# C6424_cslr_ccdc_001 register map
Vendor: Texas Instruments
Peripheral module from a debugger description file.
Registers are 32-bit, access not given, reset 0x0 unless marked. A register's access mark holds for its fields unless they carry their own. Offsets are as the file gives them; lines under a group give offsets from that group; [hi:lo] are bit positions; {n}, {i} and the like mark numbered series; 'fields as' and 'values as' point back to an identical list; <NAME> marks a mode.

## CCDC — CCD Controller (spec version: 1.00.w.29)
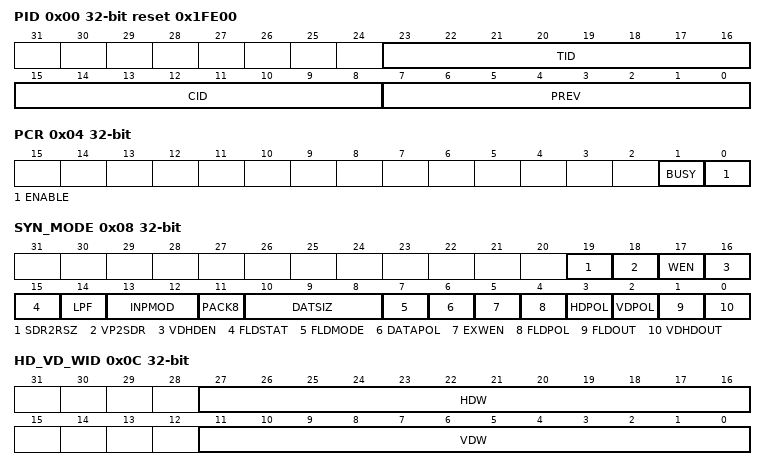
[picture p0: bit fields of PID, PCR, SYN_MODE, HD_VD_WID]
0x00 PID reset 0x1FE00 — Peripheral Revision and Class Information
  [23:16] TID ro — Peripheral Identification CCD/CMOS controller
  [15:8] CID ro — Class Identification VPFE module
  [7:0] PREV ro — Peripheral Revision Number Initial Revision
0x04 PCR — Peripheral Control Register
  [1] BUSY ro — CCDC Busy bit
    0=NOTBUSY; 1=BUSY
  [0] ENABLE rw — CCDC Enable
    0=DISABLE; 1=ENABLE
0x08 SYN_MODE — SYNC and Mode set register
  [19] SDR2RSZ rw — SDRAM port output into resizer input Controls whether or not SDRAM output data is forwarded to the resizer input port
    0=DISABLE; 1=ENABLE
  [18] VP2SDR rw — Video port output into the SDRAM port Controls whether or not video port data is forwarded to the output formatter, which in turn writes to SDRAM. Note that if field is set, then SDRAM line (VERT_START.SLVx) and pixel start (HORZ_INFO.SPH) are with respect to the video port output (and not the original input) *This bit is latched by VD
    0=DISABLE; 1=ENABLE
  [17] WEN rw — Data Write Enable Controls whether or not CCD raw data is written to SDRAM. *This bit is latched by VD
    0=DISABLE; 1=ENABLE
  [16] VDHDEN rw — VD/HD Enable If VD/HD are defined as output, activates internal timing generator. If VD/HD are defined as inputs, activates internal timing generator to synchronize with VD/HD
    0=DISABLE; 1=ENABLE
  [15] FLDSTAT ro — Field Status Indicates the status of the current field when in interlaced mode
    0=ODDFIELD; 1=EVENFIELD
  [14] LPF rw — 3-tap Low-Pass (anti-aliasing) Filter *This bit is latched by VD
    0=OFF; 1=ON
  [13:12] INPMOD rw — Setting of data input mode
    0=CCDRAW (CCD RAW data); 1=YCBCR16 (YCbCr 16-bit); 2=YCBCR8 (YCbCr 8-bit)
  [11] PACK8 rw — Pack to 8-bits/pixel (into SDRAM)
    0=_16BITS_PIXEL (normal (16 bits/pixel)); 1=_8BITS_PIXEL (pack to 8-bits/pixel)
  [10:8] DATSIZ rw — CCD Data Width valid only when INPMOD is set to '0'
    0=_16_BITS; 1=_15_BITS; 2=_14_BITS; 3=_13_BITS; 4=_12_BITS; 5=_11_BITS; 6=_10_BITS; 7=_8_BITS
  [7] FLDMODE rw — Sensor Field Mode
    0=NON_INTERLACED (non-interlaced (progressive)); 1=INTERLACED
  [6] DATAPOL rw — CCD Data Polarity
    0=NORMAL (normal (no change)); 1=ONES_COMPLEMENT
  [5] EXWEN rw — External WEN Selection When set to 1 and when VDHDEN is set to 1, the WEN signal is used as the external memory write enable (to SDRAM/DDRAM). The data is stored to memory only when the external sync (HD and VD) signals are active.
    0=NO_EXTERNAL_WEN (do not use external WEN (Write Enable)); 1=EXTERNAL_WEN (use external WEN (Write Enable))
  [4] FLDPOL rw — Field Indicator Polarity
    0=POSITIVE; 1=NEGATIVE
  [3] HDPOL rw — HD Sync Polarity
    0=POSITIVE; 1=NEGATIVE
  [2] VDPOL rw — VD Sync Polarity
    0=POSITIVE; 1=NEGATIVE
  [1] FLDOUT rw — Field ID Direction
    0=INPUT; 1=OUTPUT
  [0] VDHDOUT rw — VD/HD Sync Direction
    0=INPUT; 1=OUTPUT
0x0C HD_VD_WID — HD and VD signal width
  [27:16] HDW rw — Width of HD sync pulse if output HDW+1 pixel clocks HDWIDTH is not used when HD is input, i.e when VDHDOUT in SYN_MODE register is cleared to '0' *This bit field is latched by VD
  [11:0] VDW rw — Width of VD sync pulse if output VDW+1 lines VDWIDTH is not used when VD is input, i.e when VDHDOUT in SYN_MODE register is cleared to '0' *This bit field is latched by VD
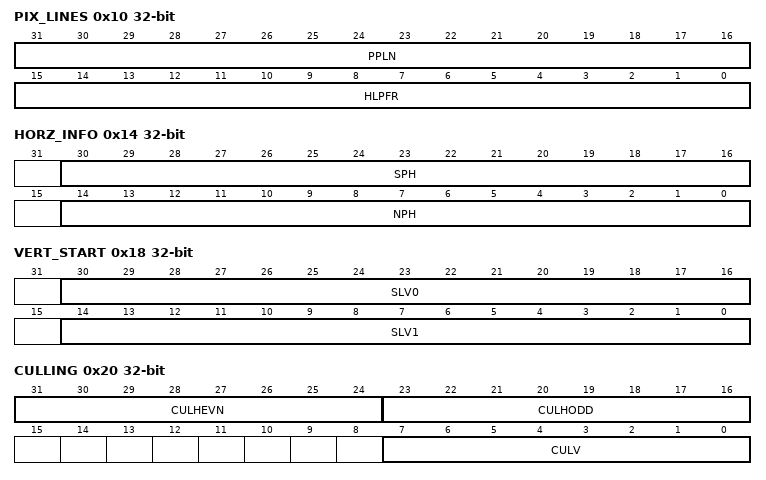
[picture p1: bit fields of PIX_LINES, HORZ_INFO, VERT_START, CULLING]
0x10 PIX_LINES rw — Number of pixels in a horizontal line and number of lines in a frame
  [31:16] PPLN — Pixels per line - number of pixel clock periods in one line HD period = PPLN+1 pixel clocks PPLN is not used when HD and VD are inputs, i.e when VDHDOUT in SYN_MODE register is cleared to '0' *This bit field is latched by VD
  [15:0] HLPFR — Half lines per field or frame - sets number of half lines per frame or field VD period = (HLPFR+1)/2 lines LPFR is not used when HD and VD are inputs, i.e when VDHDOUT in SYN_MODE register is cleared to '0' *This bit field is latched by VD This tells the internal timing generator to generate the sufficient number of HD pulses in between two VD pulses. If the sensor is an interlaced sensor, say for example, with a total of 525 (or 526) lines, then this field should be set to 525 (or 526). This means that 525 (or 526) half lines are written for each field. If the sensor is progressive, then this register should be set to be twice the number of lines to be written. For example, if sensor outputs 1024 lines, this field should be set to 2048. Therefore, for interlaced sensors, this field should be set to the total number of lines. For progressive sensors, this field should be set to twice the total number of lines.
0x14 HORZ_INFO — Horizontal pixel information
  [30:16] SPH rw — Start pixel, horizontal Sets pixel clock position at which data output to SDRAM begins, measured from the start of HD *This bit field is latched by VD
  [14:0] NPH rw — Number of pixels, horizontal Sets number of horizontal pixels that will be output to SDRAM = (NPH + 1) *This bit field is latched by VD
0x18 VERT_START — Vertical line - settings for the starting pixel
  [30:16] SLV0 rw — Start Line, Vertical (Field 0) Sets line at which data output to SDRAM will begin, measured from the start of VD *This bit field is latched by VD
  [14:0] SLV1 rw — Start Line, Vertical (Field 1) Sets line at which data output to SDRAM will begin, measured from the start of VD *This bit field is latched by VD
0x1C VERT_LINES — Number of vertical lines
  [14:0] NLV rw — Number of lines, vertical Sets number of vertical lines that will be output to SDRAM for each field. The number of lines output to SDRAM for each field = (NLV + 1). *This bit field is latched by VD
0x20 CULLING (reset mask 0xFF00) — Culling information in horizontal and vertical directions
  [31:24] CULHEVN rw — Horizontal Culling Pattern for Even Line, 8-bit mask: 0: cull, 1:retain LSB is first pixel, MSB is 8th pixel, then pattern repeats *This bit field is latched by VD
  [23:16] CULHODD rw — Horizontal Culling Pattern for Odd Line, 8-bit mask: 0: cull, 1:retain LSB is first pixel, MSB is 8th pixel, then pattern repeats *This bit field is latched by VD
  [7:0] CULV rw — Vertical Culling Pattern, 8-bit mask: 0: cull, 1:retain LSB is first line, MSB is 8th line, then pattern repeats. *This bit field is latched by VD
0x24 HSIZE_OFF — Horizontal size
  [15:0] LNOFST rw — Address offset for each line. Sets offset for each output line in SDRAM Either 16 or 32 pixels depending on setting of PACK8 *This bit field is latched by VD The 5 LSB are ignored; the offset will be on a 32-byte boundary For optimal performance in the system, the address offset should be on a 256-byte boundary.
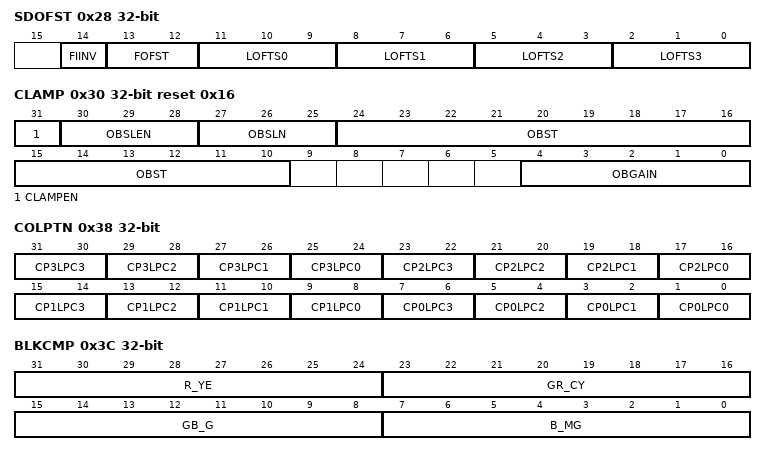
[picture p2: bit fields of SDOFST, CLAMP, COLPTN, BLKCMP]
0x28 SDOFST — SDRAM/DDRAM line offset
  [14] FIINV rw — Field identification signal inverse * This field is latched by VD
    0=NONINVERSE; 1=INVERSE
  [13:12] FOFST rw — Line offset value of field ID = 1 * This field is latched by VD
    {v}=PLUS_{v+1}LINE (+{v+1} line) (v=0..3)
  [11:9] LOFTS0 rw — Line offset values of even line and even field ID = 0 * This field is latched by VD
    0=PLUS_1LINE (+1 line); 1=PLUS_2LINES (+2 lines); 2=PLUS_3LINES (+3 lines); 3=PLUS_4LINES (+4 lines); 4=MINUS_1LINE (-1 line); 5=MINUS_2LINES (-2 lines); 6=MINUS_3LINES (-3 lines); 7=MINUS_4LINES (-4 lines)
  [8:6] LOFTS1 rw — Line offset values of odd line and even field ID = 0 * This field is latched by VD
    values as LOFTS0
  [5:3] LOFTS2 rw — Line offset values of even line and odd field ID = 1 * This field is latched by VD
    values as LOFTS0
  [2:0] LOFTS3 rw — Line offset values of odd line and odd field ID = 1 * This field is latched by VD
    values as LOFTS0
0x2C SDR_ADDR rw — SDRAM Address
  [31:0] SDR_ADDR — 32-bit SDRAM starting address for CCDC output *This bit field is latched by VD Note that the address should be aligned on a 32-byte boundary. Therefore, the 5 LSB's are ignored. Furthermore, reading this register will always show the 5 LSB's as 0. For optimal performance in the system, the address should be on a 256-byte boundary.
0x30 CLAMP reset 0x16 — Optical black clamping settings
  [31] CLAMPEN rw — Clamp Enable: Enables clamping of CCD data based on the calculated average of Optical Black Samples. *This bit is latched by VD
    0=DISABLE; 1=ENABLE
  [30:28] OBSLEN rw — Optical Black Sample Length 5-7: Reserved Number of Optical Black Sample pixels per line to include in the average calculation
    0=_1PIXELS; 1=_2PIXELS; 2=_4PIXELS; 3=_8PIXELS; 4=_16PIXELS
  [27:25] OBSLN rw — Optical Black Sample Lines 5-7: Reserved Number of Optical Black Sample lines to include in the average calculation
    0=_1LINES; 1=_2LINES; 2=_4LINES; 3=_8LINES; 4=_16LINES
  [24:10] OBST rw — Start Pixel of Optical Black Samples Start pixel position of Optical Black Samples, specified from the start of HD in pixel clocks
  [4:0] OBGAIN rw — Gain to apply to the optical black average Multiply the optical black average with the specified gain (range from 0 to ~2 - U5Q4)
0x34 DCSUB — DC clamp
  [13:0] DCSUB rw — DC level to subtract from CCD data The DC value set here is subtracted from the CCD data when OBS clamping is disabled - CLAMP:CLAMPEN
0x38 COLPTN rw — CCD color pattern
  [all] fields
    0=R; 1=GR; 2=GB; 3=B
  [2n+25:2n+24] CP3LPC{n} (n=0..3) — Color Pattern for 3rd Line, Pixel counter = {n}
  [2n+17:2n+16] CP2LPC{n} (n=0..3) — Color Pattern for 2nd Line, Pixel counter = {n}
  [2n+9:2n+8] CP1LPC{n} (n=0..3) — Color Pattern for 1st Line, Pixel counter = {n}
  [2n+1:2n] CP0LPC{n} (n=0..3) — Color Pattern for 0th Line, Pixel counter = {n}
0x3C BLKCMP rw — Black compensation
  [31:24] R_YE — Black level compensation for R pixels (-128:+127) 2's complement, MSB is sign bit
  [23:16] GR_CY — Black level compensation for Gr pixels (-128:+127) 2's complement, MSB is sign bit
  [15:8] GB_G — Black level compensation for Gb pixels (-128:+127) 2's complement, MSB is sign bit
  [7:0] B_MG — Black level compensation for B pixels (-128:+127) 2's complement, MSB is sign bit
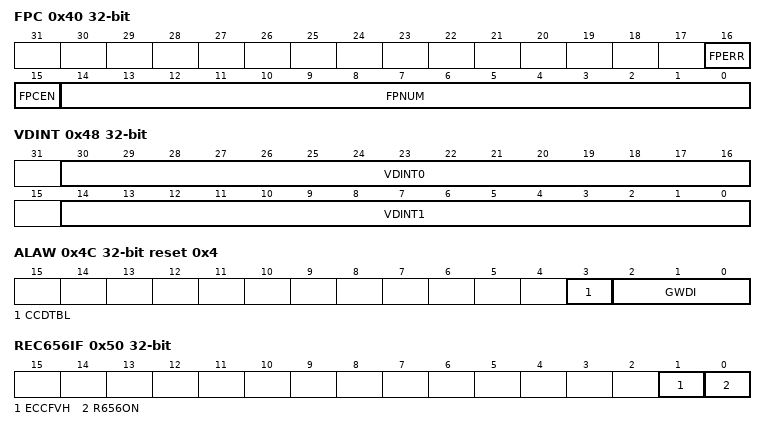
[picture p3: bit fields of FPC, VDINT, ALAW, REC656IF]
0x40 FPC — Fault pixel correction
  [16] FPERR rw — Fault pixel correction error Write 1 to clear the error This bit is set when the CCDC is unable to fetch the required fault pixel table entry in time for it to correct it. For example, the current pixel being processed has coordinates of 256/512 (256th line and 512th pixel in that line) and it needs to be corrected. If the entry in the fault pixel table that needs to be used has coordinates 256/256, then the current pixel cannot be corrected since the correct entry is not loaded in time. Note that there is no error recovery mechanism in the CCDC; if this bit is set at anytime in a frame, there will no more fault pixels corrected in that frame. Firmware is responsible for making sure that there is enough bandwidth in the system to allow for loading of the fault pixel table. Alternately, decreasing the frequency of the fault pixels to be corrected will enhance chances of this bit not being set.
    0=NOERROR; 1=ERROR
  [15] FPCEN rw — Fault pixel correction enable Upon setting this bit and as long as it remains enabled the fault pixel logic will continue to request data and just start over once the last data has been received. As soon as the register is set the data will be fetched This bit should only be written after the FPC_ADDR register below has been set. Also, the other fields in this register have to be set prior to enabling this bit. The required process is: Write(FPC_ADDR) Write(FPC) with this bit (FPC.FPCEN) turned off Write(FPC) with this bit (FPC.FPCEN) turned on while other fields are same as previous write
    0=DISABLED; 1=ENABLED
  [14:0] FPNUM rw — Number of fault pixels to be corrected in the frame *This field is latched by VD
0x44 FPC_ADDR rw — Fault pixel correction SDRAM address
  [31:0] FPC_ADDR — Starting SDRAM/DDRAM address of the fault pixel correction entries Note that the address should be aligned to a 64-byte boundary, therefore, the 6 LSB's are ignored Each of the 32-bit fault memory entry contains a 13-bit vertical position, a 14-bit horizontal position, and a 5-bit operation field The following operations are decoded by the 5-bit operation field (4:0) Note that "x" denotes the horizontal coordinate 0: replace pixel at x with the average of x-1 and x+1 1: replace pixel at x with the x-1 2: replace pixel at x with the x+1 3: replace pixel at x with the average of x-2 and x+2 4: replace pixel at x with the x-2 5: replace pixel at x with the x+2 6: replace pixel at x with the average of x-3 and x+3 7: replace pixel at x with the x-3 8: replace pixel at x with the x+3 9: replace pixel at x with the average of x-4 and x+4 10: replace pixel at x with the x-4 11: replace pixel at x with the x+4 12: replace pixel at x with the average of x-5 and x+5 13: replace pixel at x with the x-5 14: replace pixel at x with the x+5 15: replace pixel at x with the average of x-6 and x+6 16: replace pixel at x with the x-6 17: replace pixel at x with the x+6 18-31: RESERVED
0x48 VDINT — VD Interrupt Timing
  [30:16] VDINT0 rw — VD0 Interrupt Timing Specify VDINT0 in units of horiziontal lines from the start of VD pulse . Resulting value is VDINT0 + 1. Note that if the rising edge (or falling edge if programmed) of the HD lines up with the rising edge (or falling edge if programmed) of VD, the 1st HD is not counted.
  [14:0] VDINT1 rw — VD1 Interrupt Timing Specify VDINT1 in units of horizontal lines from the start of VD pulse. Resulting value is VDINT1 + 1. Note that if the rising edge (or falling edge if programmed) of the HD lines up with the rising edge (or falling edge if programmed) of VD, the 1st HD is not counted.
0x4C ALAW reset 0x4 — A-Law Setting
  [3] CCDTBL rw — Apply Gamma (A-LAW) to CCDC data saved to SDRAM
    0=DISABLE; 1=ENABLE
  [2:0] GWDI rw — Gamma Width Input (A-LAW table)
    0=BITS_15_6; 1=BITS_14_5; 2=BITS_13_4; 3=BITS_12_3; 4=BITS_11_2; 5=BITS_10_1; 6=BITS_09_0 (bits 9-0)
0x50 REC656IF — REC656 interface
  [1] ECCFVH rw — FVH Error Correction Enable
    0=DISABLE; 1=ENABLE
  [0] R656ON rw — REC656 Interface Enable
    0=DISABLE; 1=ENABLE
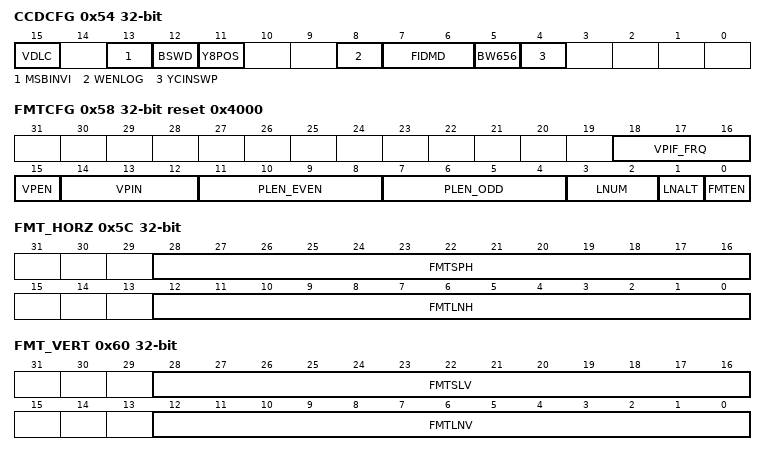
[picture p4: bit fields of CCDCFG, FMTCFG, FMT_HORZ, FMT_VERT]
0x54 CCDCFG — CCD Configuration
  [15] VDLC rw — Enable latching function registers on internal VSYNC
    0=LATCHEDONVSYNC; 1=NOTLATCHEDONVSYNC
  [13] MSBINVI rw — MSB of Chroma input signal stored to SDRAM inverted
    0=NORMAL; 1=MSBINVERTED
  [12] BSWD rw — Byte Swap Data stored to SDRAM Number of pixels must be even if byte packing is enabled (and this field is set to 1).
    0=NORMAL; 1=SWAPBYTES
  [11] Y8POS rw — Location of Y signal when YCbCr 8bit data is input
    0=EVENPIXEL; 1=ODDPIXEL
  [8] WENLOG rw — Specifies CCD valid area
    0=AND (Internal valid signal AND WEN signal is ANDed logically); 1=OR (Internal valid signal AND WEN signal is Ored logically)
  [7:6] FIDMD rw — Setting of FID detection function
    0=LATCH_AT_VSYNC (FID signal is latched at the VSYNC timing); 1=NO_LATCH (FID signal is not latched); 2=LATCH_AT_VD_EDGE (FID signal is latched at edge of VD); 3=LATCH_ON_VD_HD_PHASE (FID signal is latched based on phase of VD and HD)
  [5] BW656 rw — Data width in CCIR656 input mode Takes precedence over the SYN_MODE fields INPMOD and DATSIZ if 656 mode is enabled
    0=_8_BITS; 1=_10_BITS
  [4] YCINSWP rw — Y input (YIN[7:0]) and C input (CIN[7:0]) are swapped This field is latched on the VSYNC/VD signal
    0=NO_YCIN_SWAP (YIN[7:0] = Y signal / CIN[7:0] = C signal); 1=YCIN_SWAP (YIN[7:0] = C signal / CIN[7:0] = Y signal)
0x58 FMTCFG reset 0x4000 — Data reformatter/video port configuration
  [18:16] VPIF_FRQ rw — Video Port Data Ready Frequency This field allows the firmware to control the rate at which the video port delivers new data to the other modules (preview, h3A, and histogram). In effect, this register controls the raw output bandwidth of the preview, h3A, and histogram. Depending on the input sensor clock, the user can set this field appropriately and balance the bandwidth requirements to SDRAM. If the CCDC operating clock is 150 MHz (depends on the specific chip, please refer to chip level clocking scheme), then the following settings apply 1/2 -> Sensor cannot have pixel clock greater than 150/2 = 75 MHz 1/3.5 -> Sensor cannot have pixel clock greater than 150/3.5 = 42.8 MHz 1/4 -> Sensor cannot have pixel clock greater than 150/4.5 = 33.3 MHz 1/4 -> Sensor cannot have pixel clock greater than 150/5.5 = 27.2 MHz 1/6 -> Sensor cannot have pixel clock greater than 150/6.5 = 23 MHz Depending on the sensor speed, it is advised to apply the highest possible divisor value in this field
    0=ONE_HALF (1/2); 1=ONE_THIRDHALF (1/3.5); 2=ONE_FOURTHHALF (1/4.5); 3=ONE_FIFTHHALF (1/5.5); 4=ONE_SIXTHHALF (1/6.5)
  [15] VPEN rw — Video Port Enable
    0=DISABLE; 1=ENABLE
  [14:12] VPIN rw — Video Port Input Select (10-bit input)
    0=BITS_15_06 (bits 15-6); 1=BITS_14_05 (bits 14-5); 2=BITS_13_04 (bits 13-4); 3=BITS_12_03 (bits 12-3); 4=BITS_11_02 (bits 11-2); 5=BITS_10_01 (bits 10-1); 6=BITS_09_00 (bits 9-0)
  [11:8] PLEN_EVEN rw — Number of program entries in even line minus 1 If the desired number of program entries is 8, then this register field should be set to 7
  [7:4] PLEN_ODD rw — Number of program entries in odd line minus 1 If the desired number of program entries is 8, then this register field should be set to 7
  [3:2] LNUM rw — Number of output lines from 1 input line
    0=_1LINE; 1=_2LINES; 2=_3LINES; 3=_4LINES
  [1] LNALT rw — Line Alternating mode In Line Alternating Mode, even and odd lines are swapped.. 0th line output as 1st line and 1st line output as 0th line, and so on
    0=NORMALMODE; 1=LINEALTERNATINGMODE
  [0] FMTEN rw — CCD Formatter enable *This bit is latched by VD
    0=OFF; 1=ON
0x5C FMT_HORZ — Data reformatter/video input interface horizontal information
  [28:16] FMTSPH rw — Start pixel horizontal from start of HD
  [12:0] FMTLNH rw — Number of pixels in horizontal direction
0x60 FMT_VERT — Data reformatter/video input interface vertical information
  [28:16] FMTSLV rw — Start line from start of VD
  [12:0] FMTLNV rw — Number of lines in vertical direction
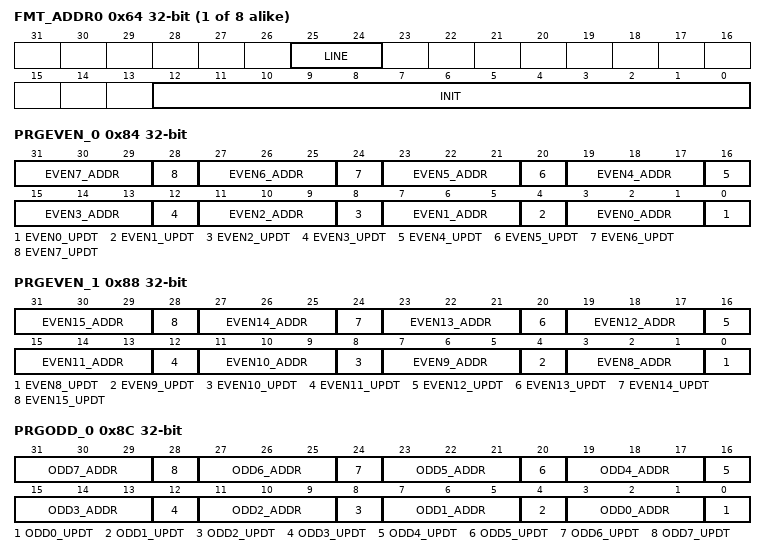
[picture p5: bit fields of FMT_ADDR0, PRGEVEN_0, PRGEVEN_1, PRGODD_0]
{0x64+4i} FMT_ADDR{i} (i=0..7) — Address pointer {i} setup
  [25:24] LINE rw — The output line the address belongs to
    0=_1STLINE; 1=_2NDLINE; 2=_3RDLINE; 3=_4THLINE
  [12:0] INIT rw — Initial address value If FMTCFG.LNUM = 0 (1-line), the maximum value of the address cannot exceed 4x1376 - 1 including the updates on it during the processing If FMTCFG.LNUM = 1 (2-line), the maximum value of the address cannot exceed 2x1376 -1 including the updates on it during the processing If FMTCFG.LNUM = 2 (3-line), the maximum value of the address cannot exceed 1376 - 1 including the updates on it during the processing If FMTCFG.LNUM = 3 (4-line), the maximum value of the address cannot exceed 1376 - 1 including the updates on it during the processing The address should always be a positive number during the updates
0x84 PRGEVEN_0 rw — Program entries 0-7 for even line
  [4n+3:4n+1] EVEN{n}_ADDR (n=0..7) — EVEN{n} Address update: Address specifier
    {v}=ADDR{v} (v=0..7)
  [4n] EVEN{n}_UPDT (n=0..7) — EVEN{n} Address update: Increment specifier
    0=INCR (ADDR* ++ (Auto increment)); 1=DECR (ADDR* -- (Auto decrement))
0x88 PRGEVEN_1 rw — Program entries 8-15 for even line
  [4n-29:4n-31] EVEN{n}_ADDR (n=10..15) — EVEN{n} Address update: Increment specifier
    {v}=ADDR{v} (v=0..7)
  [4n-32] EVEN{n}_UPDT (n=8..15) — EVEN{n} Address update: Increment specifier
    values as PRGEVEN_0.EVEN0_UPDT
  [7:5] EVEN9_ADDR — EVEN9 Address update: Address specifier
    {v}=ADDR{v} (v=0..7)
  [3:1] EVEN8_ADDR — EVEN8 Address update: Address specifier
    {v}=ADDR{v} (v=0..7)
0x8C PRGODD_0 rw — Program entries 0-7 for odd line
  [4n+3:4n+1] ODD{n}_ADDR (n=0..7) — ODD{n} Address update: Address specifier
    {v}=ADDR{v} (v=0..7)
  [4n] ODD{n}_UPDT (n=0..7) — ODD{n} Address update: Increment specifier
    values as PRGEVEN_0.EVEN0_UPDT
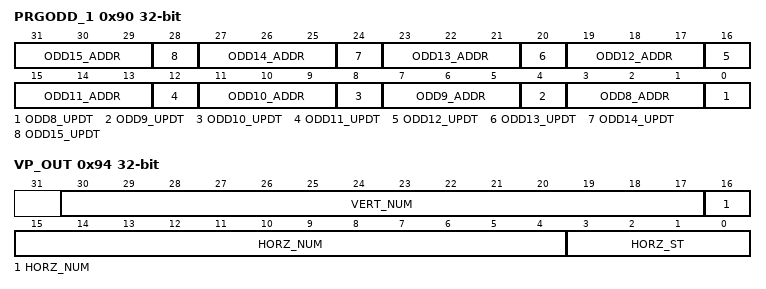
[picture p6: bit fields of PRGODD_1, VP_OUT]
0x90 PRGODD_1 rw — Program entries 8-15 for odd line
  [4n-29:4n-31] ODD{n}_ADDR (n=8..15) — ODD{n} Address update: Address specifier
    {v}=ADDR{v} (v=0..7)
  [4n-32] ODD{n}_UPDT (n=8..15) — ODD{n} Address update: Increment specifier
    values as PRGEVEN_0.EVEN0_UPDT
0x94 VP_OUT — Video port output settings
  [30:17] VERT_NUM rw — Number of vertical lines to clock out the video port The video port output is the input to the preview engine, h3A, and histogram modules (if selected for each module). If the data reformatter is turned off, then the number of lines that can be clocked out of the video port should be at least 1 line less than the number of lines input from the sensor. If the data reformatter is turned on, then the number of lines that can be clocked out of the video port should be less than (FMT_VERT.FMTLNV 1) * (FMTCFG.LNUM + 1) The video port output VSYNC is generated right from the 1st video port input VSYNC itself
  [16:4] HORZ_NUM rw — Number of horizontal pixels to clock out the video port Maximum offset allowed is 1376 if original input is broken down to 4 lines Maximum offset allowed is 1376 if original input is broken down to 3 lines Maximum offset allowed is 2*1376 if original input is broken down to 2 lines Maximum offset allowed is 4*1376 if original input is broken down to 1 line
  [3:0] HORZ_ST rw — Horizontal start pixel in each output line Maximum offset allowed is 15, the video port output HSYNC is generated from this position on for each line. In order to be able to select an offset higher than 15, the input settings to the data reformatter should be configured appropriately. The purpose of this parameter is to allow for sensors that can read out a parallelogram image rather than a rectangular image
